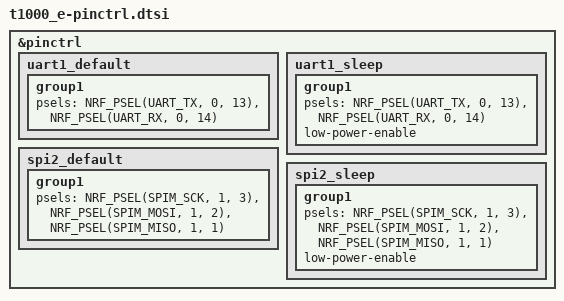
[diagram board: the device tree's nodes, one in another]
/*
 * SPDX-License-Identifier: GPL-3.0-or-later
 * SPDX-FileCopyrightText: The contributors to the LICHEN project
 *
 * Seeed SenseCAP T1000-E pin assignments.
 *
 * WARNING: Pin assignments below are UNVERIFIED PLACEHOLDERS.
 * Verify every assignment against the T1000-E schematic before
 * flashing.  The Amazon Sidewalk SDK hw_config.h is a good reference.
 *
 * Known-safe placeholders on port 1 (P1.xx) are used so that
 * incorrect assignments drive floating GPIO pins rather than
 * critical resources.
 */

&pinctrl {
	/*
	 * UART1: AG3335 GNSS (verified against Meshtastic variant.h)
	 *   TX = P0.13  RX = P0.14
	 */
	uart1_default: uart1_default {
		group1 {
			psels = <NRF_PSEL(UART_TX, 0, 13)>,
				<NRF_PSEL(UART_RX, 0, 14)>;
		};
	};
	uart1_sleep: uart1_sleep {
		group1 {
			psels = <NRF_PSEL(UART_TX, 0, 13)>,
				<NRF_PSEL(UART_RX, 0, 14)>;
			low-power-enable;
		};
	};

	/*
	 * SPI2: LR1110 radio
	 * TODO: replace with verified pin numbers from T1000-E schematic.
	 *   SCK  = P1.03 (placeholder)
	 *   MOSI = P1.02 (placeholder)
	 *   MISO = P1.01 (placeholder)
	 *   CS   = P1.04 via cs-gpios (placeholder)
	 */
	spi2_default: spi2_default {
		group1 {
			psels = <NRF_PSEL(SPIM_SCK,  1, 3)>,
				<NRF_PSEL(SPIM_MOSI, 1, 2)>,
				<NRF_PSEL(SPIM_MISO, 1, 1)>;
		};
	};
	spi2_sleep: spi2_sleep {
		group1 {
			psels = <NRF_PSEL(SPIM_SCK,  1, 3)>,
				<NRF_PSEL(SPIM_MOSI, 1, 2)>,
				<NRF_PSEL(SPIM_MISO, 1, 1)>;
			low-power-enable;
		};
	};
};
